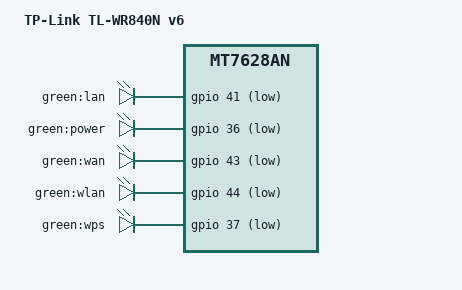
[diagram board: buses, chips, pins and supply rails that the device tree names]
#include "mt7628an_tplink_tl-wr840n-v6.x.dts"

/ {
	compatible = "tplink,tl-wr840n-v6", "mediatek,mt7628an-soc";
	model = "TP-Link TL-WR840N v6";

	aliases {
		led-boot = &led_power;
		led-failsafe = &led_power;
		led-running = &led_power;
		led-upgrade = &led_power;
	};

	leds {
		compatible = "gpio-leds";

		lan {
			label = "green:lan";
			gpios = <&gpio 41 GPIO_ACTIVE_LOW>;
		};

		led_power: power {
			label = "green:power";
			gpios = <&gpio 36 GPIO_ACTIVE_LOW>;
		};

		wan {
			label = "green:wan";
			gpios = <&gpio 43 GPIO_ACTIVE_LOW>;
		};

		wlan {
			label = "green:wlan";
			gpios = <&gpio 44 GPIO_ACTIVE_LOW>;
		};

		wps {
			label = "green:wps";
			gpios = <&gpio 37 GPIO_ACTIVE_LOW>;
		};
	};
};

&ralinkgpio {
	groups = "p0led_an", "p2led_an", "perst", "wdt";
};
